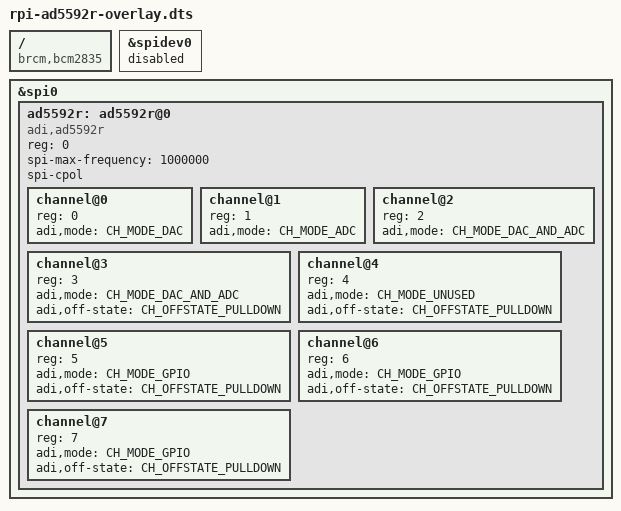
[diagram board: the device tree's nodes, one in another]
// SPDX-License-Identifier: GPL-2.0
/dts-v1/;
/plugin/;

#include <dt-bindings/iio/adi,ad5592r.h>

/ {
	compatible = "brcm,bcm2835";

	fragment@0 {
		target = <&spidev0>;

		__overlay__ {
			status = "disabled";
		};
	};

	fragment@1 {
		target = <&spi0>;
		__overlay__ {
			#size-cells = <0>;
			#address-cells = <1>;
			status = "okay";

			ad5592r: ad5592r@0 {
				compatible = "adi,ad5592r";
				reg = <0>;

				spi-max-frequency = <1000000>;
				spi-cpol;

				channel@0 {
					reg = <0>;
					adi,mode = <CH_MODE_DAC>;
				};
				channel@1 {
					reg = <1>;
					adi,mode = <CH_MODE_ADC>;
				};
				channel@2 {
					reg = <2>;
					adi,mode = <CH_MODE_DAC_AND_ADC>;
				};
				channel@3 {
					reg = <3>;
					adi,mode = <CH_MODE_DAC_AND_ADC>;
					adi,off-state = <CH_OFFSTATE_PULLDOWN>;
				};
				channel@4 {
					reg = <4>;
					adi,mode = <CH_MODE_UNUSED>;
					adi,off-state = <CH_OFFSTATE_PULLDOWN>;
				};
				channel@5 {
					reg = <5>;
					adi,mode = <CH_MODE_GPIO>;
					adi,off-state = <CH_OFFSTATE_PULLDOWN>;
				};
				channel@6 {
					reg = <6>;
					adi,mode = <CH_MODE_GPIO>;
					adi,off-state = <CH_OFFSTATE_PULLDOWN>;
				};
				channel@7 {
					reg = <7>;
					adi,mode = <CH_MODE_GPIO>;
					adi,off-state = <CH_OFFSTATE_PULLDOWN>;
				};
			};
		};
	};
	__overrides__ {
		cs_pin = <&ad5592r>,"reg:0";
	};
};
